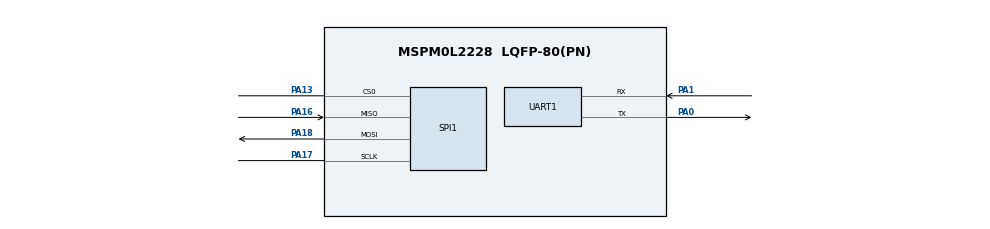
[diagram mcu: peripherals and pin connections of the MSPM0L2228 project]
//@cliArgs --device "MSPM0L222X" --package "LQFP-80(PN)" --part "Default"
//@v2CliArgs --device "MSPM0L2228" --package "LQFP-80(PN)"
// @cliArgs --board /ti/boards/LP_MSPM0L2228 --rtos nortos

/**
 * Import the modules used in this configuration.
 */
const SPI           = scripting.addModule("/ti/driverlib/SPI", {}, false);
const SPI1          = SPI.addInstance();
const SYSCTL        = scripting.addModule("/ti/driverlib/SYSCTL");
const UART          = scripting.addModule("/ti/driverlib/UART", {}, false);
const UART1         = UART.addInstance();
const ProjectConfig = scripting.addModule("/ti/project_config/ProjectConfig");

/**
 * Write custom configuration values to the imported modules.
 */
const mux8 = system.clockTree["LFXTMUX"];
scripting.suppress("Note: VBAT needs to be powered for LFCLK operation\\.", mux8, "inputSelect");

SPI1.$name                      = "SPI_0";
SPI1.enabledInterrupts          = ["PARITY_ERROR","RX","RX_FULL","RX_OVERFLOW","RX_TIMEOUT","TX","TX_UNDERFLOW"];
SPI1.rxFifoThreshold            = "DL_SPI_RX_FIFO_LEVEL_ONE_FRAME";
SPI1.peripheral.$assign         = "SPI1";
SPI1.peripheral.sclkPin.$assign = "PA17";
SPI1.peripheral.mosiPin.$assign = "PA18";
SPI1.peripheral.misoPin.$assign = "PA16";
SPI1.peripheral.cs0Pin.$assign  = "PA13";

const Board              = scripting.addModule("/ti/driverlib/Board", {}, false);
Board.peripheral.$assign = "DEBUGSS";

SYSCTL.clockTreeEn           = true;
SYSCTL.forceDefaultClkConfig = true;

UART1.rxFifoThreshold                  = "DL_UART_RX_FIFO_LEVEL_ONE_ENTRY";
UART1.enableDMARX                      = false;
UART1.enableDMATX                      = false;
UART1.enabledInterrupts                = ["RX"];
UART1.$name                            = "UART_BRIDGE";
UART1.peripheral.$assign               = "UART0";
UART1.peripheral.rxPin.$assign         = "PA1";
UART1.peripheral.txPin.$assign         = "PA0";

ProjectConfig.switchCondition = true;
scripting.suppress("Migrating requires going through the Switch Board or Device menu in the Device View section\\.", ProjectConfig, "deviceSpin");
